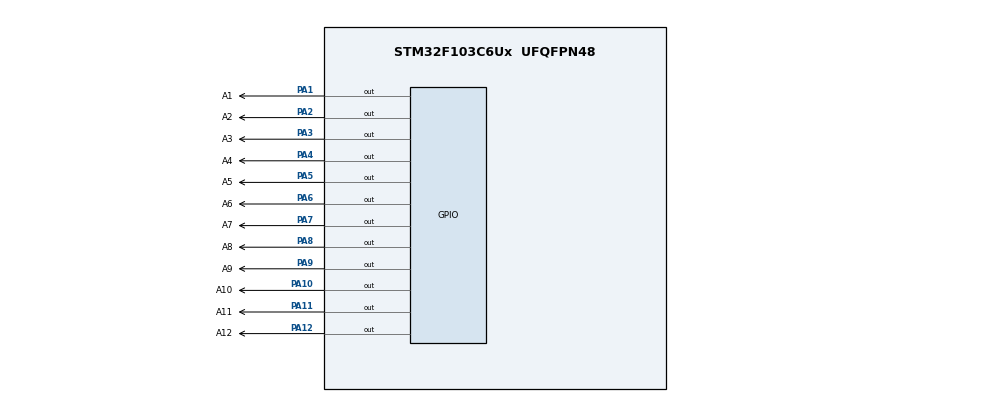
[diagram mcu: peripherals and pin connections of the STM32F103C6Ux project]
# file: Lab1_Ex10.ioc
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Mcu.Family=STM32F1
Mcu.Name=STM32F103C6Ux
Mcu.Package=UFQFPN48
NVIC.PriorityGroup=NVIC_PRIORITYGROUP_4
PA1.GPIO_Label=A1
PA1.Signal=GPIO_Output
PA10.GPIO_Label=A10
PA10.Signal=GPIO_Output
PA11.GPIO_Label=A11
PA11.Signal=GPIO_Output
PA12.GPIO_Label=A12
PA12.Signal=GPIO_Output
PA2.GPIO_Label=A2
PA2.Signal=GPIO_Output
PA3.GPIO_Label=A3
PA3.Signal=GPIO_Output
PA4.GPIO_Label=A4
PA4.Signal=GPIO_Output
PA5.GPIO_Label=A5
PA5.Signal=GPIO_Output
PA6.GPIO_Label=A6
PA6.Signal=GPIO_Output
PA7.GPIO_Label=A7
PA7.Signal=GPIO_Output
PA8.GPIO_Label=A8
PA8.Signal=GPIO_Output
PA9.GPIO_Label=A9
PA9.Signal=GPIO_Output
ProjectManager.HeapSize=0x200
ProjectManager.StackSize=0x400
ProjectManager.TargetToolchain=STM32CubeIDE
RCC.APB1Freq_Value=8000000
RCC.APB2Freq_Value=8000000
VP_SYS_VS_ND.Mode=No_Debug
board=custom

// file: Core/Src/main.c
/* USER CODE BEGIN Header */
/**
  ******************************************************************************
  * @file           : main.c
  * @brief          : Main program body
  ******************************************************************************
  * @attention
  *
  * <h2><center>&copy; Copyright (c) 2025 STMicroelectronics.
  * All rights reserved.</center></h2>
  *
  * This software component is licensed by ST under BSD 3-Clause license,
  * the "License"; You may not use this file except in compliance with the
  * License. You may obtain a copy of the License at:
  *                        opensource.org/licenses/BSD-3-Clause
  *
  ******************************************************************************
  */
/* USER CODE END Header */
#include "main.h"

void SystemClock_Config(void);
static void MX_GPIO_Init(void);

void clearALLClock(){
	HAL_GPIO_WritePin(A1_GPIO_Port, A1_Pin, GPIO_PIN_SET);
	HAL_GPIO_WritePin(A2_GPIO_Port, A2_Pin, GPIO_PIN_SET);
	HAL_GPIO_WritePin(A3_GPIO_Port, A3_Pin, GPIO_PIN_SET);
	HAL_GPIO_WritePin(A4_GPIO_Port, A4_Pin, GPIO_PIN_SET);
	HAL_GPIO_WritePin(A5_GPIO_Port, A5_Pin, GPIO_PIN_SET);
	HAL_GPIO_WritePin(A6_GPIO_Port, A6_Pin, GPIO_PIN_SET);
	HAL_GPIO_WritePin(A7_GPIO_Port, A7_Pin, GPIO_PIN_SET);
	HAL_GPIO_WritePin(A8_GPIO_Port, A8_Pin, GPIO_PIN_SET);
	HAL_GPIO_WritePin(A9_GPIO_Port, A9_Pin, GPIO_PIN_SET);
	HAL_GPIO_WritePin(A10_GPIO_Port, A10_Pin, GPIO_PIN_SET);
	HAL_GPIO_WritePin(A11_GPIO_Port, A11_Pin, GPIO_PIN_SET);
	HAL_GPIO_WritePin(A12_GPIO_Port, A12_Pin, GPIO_PIN_SET);
}

void setNumberOnClock(int num){
	switch (num){
		case 0:
		{
			HAL_GPIO_WritePin(A1_GPIO_Port, A1_Pin, GPIO_PIN_RESET);
			break;
		}
		case 1:
		{
			HAL_GPIO_WritePin(A2_GPIO_Port, A2_Pin, GPIO_PIN_RESET);
			break;
		}
		case 2:
		{
			HAL_GPIO_WritePin(A3_GPIO_Port, A3_Pin, GPIO_PIN_RESET);
			break;
		}
		case 3:
		{
			HAL_GPIO_WritePin(A4_GPIO_Port, A4_Pin, GPIO_PIN_RESET);
			break;
		}
		case 4:
		{
			HAL_GPIO_WritePin(A5_GPIO_Port, A5_Pin, GPIO_PIN_RESET);
			break;
		}
		case 5:
		{
			HAL_GPIO_WritePin(A6_GPIO_Port, A6_Pin, GPIO_PIN_RESET);
			break;
		}
		case 6:
		{
			HAL_GPIO_WritePin(A7_GPIO_Port, A7_Pin, GPIO_PIN_RESET);
			break;
		}
		case 7:
		{
			HAL_GPIO_WritePin(A8_GPIO_Port, A8_Pin, GPIO_PIN_RESET);
			break;
		}
		case 8:
		{
			HAL_GPIO_WritePin(A9_GPIO_Port, A9_Pin, GPIO_PIN_RESET);
			break;
		}
		case 9:
		{
			HAL_GPIO_WritePin(A10_GPIO_Port, A10_Pin, GPIO_PIN_RESET);
			break;
		}
		case 10:
		{
			HAL_GPIO_WritePin(A11_GPIO_Port, A11_Pin, GPIO_PIN_RESET);
			break;
		}
		case 11:
		{
			HAL_GPIO_WritePin(A12_GPIO_Port, A12_Pin, GPIO_PIN_RESET);
			break;
		}
		default:
			break;
	}
}

void clearNumberOnClock(int num){
	switch (num){
			case 0:
			{
				HAL_GPIO_WritePin(A1_GPIO_Port, A1_Pin, GPIO_PIN_SET);
				break;
			}
			case 1:
			{
				HAL_GPIO_WritePin(A2_GPIO_Port, A2_Pin, GPIO_PIN_SET);
				break;
			}
			case 2:
			{
				HAL_GPIO_WritePin(A3_GPIO_Port, A3_Pin, GPIO_PIN_SET);
				break;
			}
			case 3:
			{
				HAL_GPIO_WritePin(A4_GPIO_Port, A4_Pin, GPIO_PIN_SET);
				break;
			}
			case 4:
			{
				HAL_GPIO_WritePin(A5_GPIO_Port, A5_Pin, GPIO_PIN_SET);
				break;
			}
			case 5:
			{
				HAL_GPIO_WritePin(A6_GPIO_Port, A6_Pin, GPIO_PIN_SET);
				break;
			}
			case 6:
			{
				HAL_GPIO_WritePin(A7_GPIO_Port, A7_Pin, GPIO_PIN_SET);
				break;
			}
			case 7:
			{
				HAL_GPIO_WritePin(A8_GPIO_Port, A8_Pin, GPIO_PIN_SET);
				break;
			}
			case 8:
			{
				HAL_GPIO_WritePin(A9_GPIO_Port, A9_Pin, GPIO_PIN_SET);
				break;
			}
			case 9:
			{
				HAL_GPIO_WritePin(A10_GPIO_Port, A10_Pin, GPIO_PIN_SET);
				break;
			}
			case 10:
			{
				HAL_GPIO_WritePin(A11_GPIO_Port, A11_Pin, GPIO_PIN_SET);
				break;
			}
			case 11:
			{
				HAL_GPIO_WritePin(A12_GPIO_Port, A12_Pin, GPIO_PIN_SET);
				break;
			}
			default:
				break;
		}
}

void displayClock(int hour, int minute, int second) {
    clearALLClock();

    int h = hour % 12;
    int m = minute / 5;
    int s = second / 5;

    setNumberOnClock(h);
    setNumberOnClock(m);
    setNumberOnClock(s);
}

int main(void)
{

  /* MCU Configuration--------------------------------------------------------*/

  /* Reset of all peripherals, Initializes the Flash interface and the Systick. */
  HAL_Init();

  /* Configure the system clock */
  SystemClock_Config();

  /* Initialize all configured peripherals */
  MX_GPIO_Init();

  /* Infinite loop */
  /* USER CODE BEGIN WHILE */

  int hour = 1;
  int minute = 50;
  int second = 0;

  while (1)
  {
	  displayClock(hour, minute, second);

	  HAL_Delay(3);

	  second++;
	  if (second == 60) {
	      second = 0;
	      minute++;
	      if (minute == 60) {
	          minute = 0;
	          hour++;
	          if (hour == 12) hour = 0;
	      }
	  }

    /* USER CODE END WHILE */

  }
}

void SystemClock_Config(void)
{
  RCC_OscInitTypeDef RCC_OscInitStruct = {0};
  RCC_ClkInitTypeDef RCC_ClkInitStruct = {0};

  /** Initializes the RCC Oscillators according to the specified parameters
  * in the RCC_OscInitTypeDef structure.
  */
  RCC_OscInitStruct.OscillatorType = RCC_OSCILLATORTYPE_HSI;
  RCC_OscInitStruct.HSIState = RCC_HSI_ON;
  RCC_OscInitStruct.HSICalibrationValue = RCC_HSICALIBRATION_DEFAULT;
  RCC_OscInitStruct.PLL.PLLState = RCC_PLL_NONE;
  if (HAL_RCC_OscConfig(&RCC_OscInitStruct) != HAL_OK)
  {
    Error_Handler();
  }
  /** Initializes the CPU, AHB and APB buses clocks
  */
  RCC_ClkInitStruct.ClockType = RCC_CLOCKTYPE_HCLK|RCC_CLOCKTYPE_SYSCLK
                              |RCC_CLOCKTYPE_PCLK1|RCC_CLOCKTYPE_PCLK2;
  RCC_ClkInitStruct.SYSCLKSource = RCC_SYSCLKSOURCE_HSI;
  RCC_ClkInitStruct.AHBCLKDivider = RCC_SYSCLK_DIV1;
  RCC_ClkInitStruct.APB1CLKDivider = RCC_HCLK_DIV1;
  RCC_ClkInitStruct.APB2CLKDivider = RCC_HCLK_DIV1;

  if (HAL_RCC_ClockConfig(&RCC_ClkInitStruct, FLASH_LATENCY_0) != HAL_OK)
  {
    Error_Handler();
  }
}

static void MX_GPIO_Init(void)
{
  GPIO_InitTypeDef GPIO_InitStruct = {0};

  /* GPIO Ports Clock Enable */
  __HAL_RCC_GPIOA_CLK_ENABLE();

  /*Configure GPIO pin Output Level */
  HAL_GPIO_WritePin(GPIOA, A1_Pin|A2_Pin|A3_Pin|A4_Pin
                          |A5_Pin|A6_Pin|A7_Pin|A8_Pin
                          |A9_Pin|A10_Pin|A11_Pin|A12_Pin, GPIO_PIN_SET);

  /*Configure GPIO pins : A1_Pin A2_Pin A3_Pin A4_Pin
                           A5_Pin A6_Pin A7_Pin A8_Pin
                           A9_Pin A10_Pin A11_Pin A12_Pin */
  GPIO_InitStruct.Pin = A1_Pin|A2_Pin|A3_Pin|A4_Pin
                          |A5_Pin|A6_Pin|A7_Pin|A8_Pin
                          |A9_Pin|A10_Pin|A11_Pin|A12_Pin;
  GPIO_InitStruct.Mode = GPIO_MODE_OUTPUT_PP;
  GPIO_InitStruct.Pull = GPIO_NOPULL;
  GPIO_InitStruct.Speed = GPIO_SPEED_FREQ_LOW;
  HAL_GPIO_Init(GPIOA, &GPIO_InitStruct);

}

void Error_Handler(void)
{
  __disable_irq();
  while (1)
  {
  }
}

/************************ (C) COPYRIGHT STMicroelectronics *****END OF FILE****/
